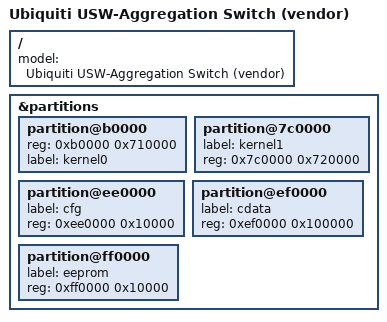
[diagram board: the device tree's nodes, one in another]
// SPDX-License-Identifier: (GPL-2.0-or-later OR MIT)
/dts-v1/;

#include "rtl9303_ubiquiti-usw-aggregation.dts"

/ {
	model = "Ubiquiti USW-Aggregation Switch (vendor)";
};

&partitions {
	/delete-node/ partition@b0000;

	partition@b0000 {
		reg = <0xb0000 0x710000>;
		label = "kernel0";
	};

	partition@7c0000 {
		label = "kernel1";
		reg = <0x7c0000 0x720000>;
	};

	partition@ee0000 {
		label = "cfg";
		reg = <0xee0000 0x10000>;
	};

	partition@ef0000 {
		label = "cdata";
		reg = <0xef0000 0x100000>;
	};

	partition@ff0000 {
		label = "eeprom";
		reg = <0xff0000 0x10000>;
	};
};
